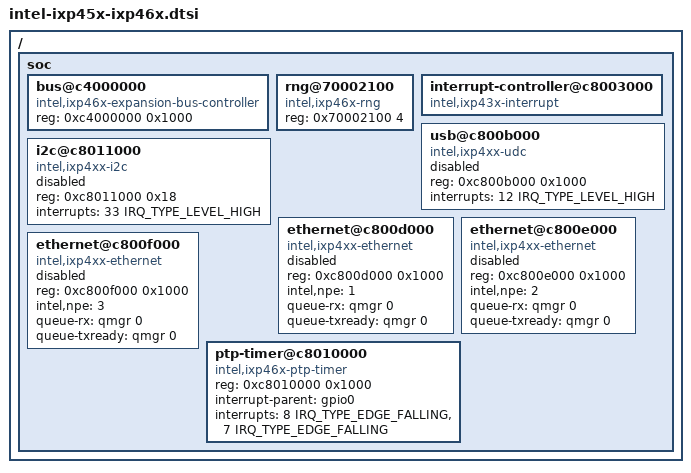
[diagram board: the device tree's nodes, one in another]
#include "intel-ixp4xx.dtsi"
/ {
	soc {
		bus@c4000000 {
			compatible = "intel,ixp46x-expansion-bus-controller", "syscon";
			reg = <0xc4000000 0x1000>;
		};
		rng@70002100 {
			compatible = "intel,ixp46x-rng";
			reg = <0x70002100 4>;
		};
		interrupt-controller@c8003000 {
			compatible = "intel,ixp43x-interrupt";
		};
		usb@c800b000 {
			compatible = "intel,ixp4xx-udc";
			reg = <0xc800b000 0x1000>;
			interrupts = <12 IRQ_TYPE_LEVEL_HIGH>;
			status = "disabled";
		};
		i2c@c8011000 {
			compatible = "intel,ixp4xx-i2c";
			reg = <0xc8011000 0x18>;
			interrupts = <33 IRQ_TYPE_LEVEL_HIGH>;
			status = "disabled";
		};
		ethernet@c800d000 {
			compatible = "intel,ixp4xx-ethernet";
			reg = <0xc800d000 0x1000>;
			status = "disabled";
			intel,npe = <1>;
			queue-rx = <&qmgr 0>;
			queue-txready = <&qmgr 0>;
		};
		ethernet@c800e000 {
			compatible = "intel,ixp4xx-ethernet";
			reg = <0xc800e000 0x1000>;
			status = "disabled";
			intel,npe = <2>;
			queue-rx = <&qmgr 0>;
			queue-txready = <&qmgr 0>;
		};
		ethernet@c800f000 {
			compatible = "intel,ixp4xx-ethernet";
			reg = <0xc800f000 0x1000>;
			status = "disabled";
			intel,npe = <3>;
			queue-rx = <&qmgr 0>;
			queue-txready = <&qmgr 0>;
		};
		ptp-timer@c8010000 {
			compatible = "intel,ixp46x-ptp-timer";
			reg = <0xc8010000 0x1000>;
			interrupt-parent = <&gpio0>;
			interrupts = <8 IRQ_TYPE_EDGE_FALLING>, <7 IRQ_TYPE_EDGE_FALLING>;
			interrupt-names = "master", "slave";
		};
	};
};
